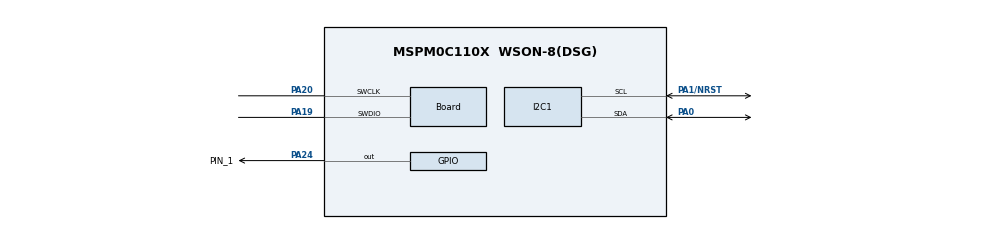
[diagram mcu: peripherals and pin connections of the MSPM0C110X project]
/**
 * @cliArgs --device "MSPM0C110X" --part "Default" --package "WSON-8(DSG)" --product "mspm0_sdk@2.03.00.08"
 * @versions {"tool":"1.22.0+3893"}
 */

/**
 * Import the modules used in this configuration.
 */
const Board  = scripting.addModule("/ti/driverlib/Board");
const GPIO   = scripting.addModule("/ti/driverlib/GPIO", {}, false);
const GPIO1  = GPIO.addInstance();
const GPIO2  = GPIO.addInstance();
const I2C    = scripting.addModule("/ti/driverlib/I2C", {}, false);
const I2C1   = I2C.addInstance();
const SYSCTL = scripting.addModule("/ti/driverlib/SYSCTL");
const TIMER  = scripting.addModule("/ti/driverlib/TIMER", {}, false);
const TIMER1 = TIMER.addInstance();
const TIMER2 = TIMER.addInstance();

/**
 * Write custom configuration values to the imported modules.
 */
Board.peripheral.$assign          = "DEBUGSS";
Board.peripheral.swclkPin.$assign = "PA20";
Board.peripheral.swdioPin.$assign = "PA19";

GPIO1.$name                         = "LED_RED";
GPIO1.port                          = "PORTA";
GPIO1.associatedPins[0].$name       = "PIN_0";
GPIO1.associatedPins[0].ioStructure = "SD";

GPIO2.$name                         = "LED_GREEN";
GPIO2.port                          = "PORTA";
GPIO2.associatedPins[0].$name       = "PIN_1";
GPIO2.associatedPins[0].ioStructure = "SD";
GPIO2.associatedPins[0].pin.$assign = "PA24";

I2C1.$name                             = "I2C";
I2C1.basicEnableController             = true;
I2C1.basicControllerBusSpeed           = 400000;
I2C1.advAnalogGlitchFilter             = "DISABLED";
I2C1.basicControllerStandardBusSpeed   = "Fast";
I2C1.advControllerRXFIFOTRIG           = "BYTES_2";
I2C1.peripheral.$assign                = "I2C0";
I2C1.peripheral.sdaPin.$assign         = "PA0";
I2C1.peripheral.sclPin.$assign         = "PA1/NRST";
I2C1.sdaPinConfig.$name                = "ti_driverlib_gpio_GPIOPinGeneric0";
I2C1.sdaPinConfig.hideOutputInversion  = scripting.forceWrite(false);
I2C1.sdaPinConfig.onlyInternalResistor = scripting.forceWrite(false);
I2C1.sdaPinConfig.passedPeripheralType = scripting.forceWrite("Digital");
I2C1.sdaPinConfig.hysteresisControl    = "ENABLE";
I2C1.sclPinConfig.$name                = "ti_driverlib_gpio_GPIOPinGeneric1";
I2C1.sclPinConfig.hideOutputInversion  = scripting.forceWrite(false);
I2C1.sclPinConfig.onlyInternalResistor = scripting.forceWrite(false);
I2C1.sclPinConfig.passedPeripheralType = scripting.forceWrite("Digital");
I2C1.sclPinConfig.hysteresisControl    = "ENABLE";

SYSCTL.clockTreeEn    = true;
SYSCTL.disableNRSTPin = true;
SYSCTL.powerPolicy    = "STANDBY0";

TIMER1.$name              = "TIMER_0";
TIMER1.timerClkSrc        = "LFCLK";
TIMER1.timerClkPrescale   = 33;
TIMER1.timerMode          = "PERIODIC";
TIMER1.interrupts         = ["ZERO"];
TIMER1.timerPeriod        = "500ms";
TIMER1.peripheral.$assign = "TIMG14";

TIMER2.$name              = "TIMER_1";
TIMER2.timerMode          = "PERIODIC";
TIMER2.interrupts         = ["ZERO"];
TIMER2.timerClkPrescale   = 256;
TIMER2.timerPeriod        = "250ms";
TIMER2.peripheral.$assign = "TIMG8";

const ProjectConfig              = scripting.addModule("/ti/project_config/ProjectConfig", {}, false);
ProjectConfig.migrationCondition = true;

/**
 * Pinmux solution for unlocked pins/peripherals. This ensures that minor changes to the automatic solver in a future
 * version of the tool will not impact the pinmux you originally saw.  These lines can be completely deleted in order to
 * re-solve from scratch.
 */
GPIO1.associatedPins[0].pin.$suggestSolution = "PA27";
